# SMS_LITE_MAILBOX_4_MAILBOX_44242000h register map
Vendor: Texas Instruments
Peripheral module from a debugger description file (folder am62L).
Registers are 32-bit, read-write, reset 0x0 unless marked. A register's access mark holds for its fields unless they carry their own. Offsets are as the file gives them; lines under a group give offsets from that group; [hi:lo] are bit positions; {n}, {i} and the like mark numbered series; 'fields as' and 'values as' point back to an identical list; <NAME> marks a mode.

## mailbox
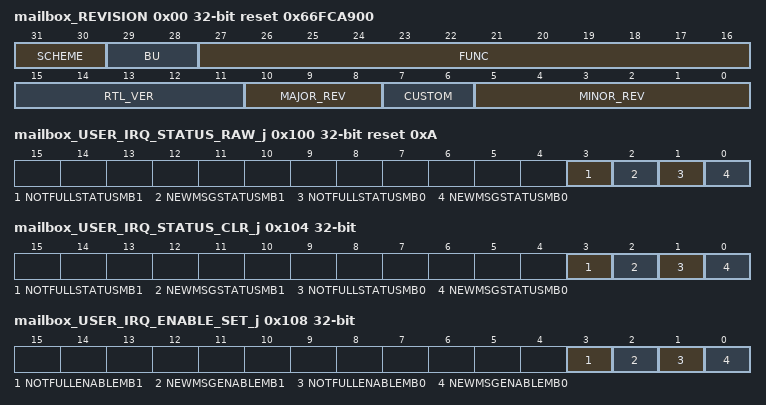
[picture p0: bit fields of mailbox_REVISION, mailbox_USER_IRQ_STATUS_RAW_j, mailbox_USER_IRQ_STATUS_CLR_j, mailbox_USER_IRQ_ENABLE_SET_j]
0x00 mailbox_REVISION ro reset 0x66FCA900 — This is the standard TI peripheral ID register that exists at address 0 in the peripheral space
  [31:30] SCHEME — Used to distinguish which ID numbering scheme is used. Reset Source: sms_custom_rst_mod_g_rst_n
  [29:28] BU — BU identifier Reset Source: sms_custom_rst_mod_g_rst_n
  [27:16] FUNC — Module family. Reset Source: sms_custom_rst_mod_g_rst_n
  [15:11] RTL_VER — RTL version. R of X.Y.R.Z Reset Source: sms_custom_rst_mod_g_rst_n
  [10:8] MAJOR_REV — Major revision. X of X.Y.R.Z Reset Source: sms_custom_rst_mod_g_rst_n
  [7:6] CUSTOM — Special version number Reset Source: sms_custom_rst_mod_g_rst_n
  [5:0] MINOR_REV — Minor revision. Y of X.Y.R.Z Reset Source: sms_custom_rst_mod_g_rst_n
0x10 mailbox_SYSCONFIG — This register contains parameters to control the whole Mailbox system. Provided for backwards compatibility with OMAP Mailbox. Only contains the soft reset.
  [0] SOFT_RESET — Module Software ResetThe bit is automatically reset by the hardware. During reads, it always returns 0.It has the same effect as the hardware reset.Writing a 0 has no effect. Writing a 1 will start a soft reset sequence and empty all the mailboxes Reset Source: sms_custom_rst_mod_g_rst_n
0x40 mailbox_MESSAGE_j — The message register stores the next to-be-read message of the mailbox. Read: Reads the next available message. Write: Add a message to this mailbox queue.
  [31:0] MESSAGE_VALUE — Message in Mailbox [a] Reset Source: sms_custom_rst_mod_g_rst_n
0x80 mailbox_FIFO_STATUS_j ro — The FIFO status register has the status of the Mailbox[a] FIFO
  [0] FIFO_FULL — Full flag for Mailbox m Reset Source: sms_custom_rst_mod_g_rst_n
0xC0 mailbox_MSG_STATUS_j ro — The message status register has the status of the messages in Mailbox[a]
  [2:0] NUM_MESSAGES — Number of messages in Mailbox[a] Reset Source: sms_custom_rst_mod_g_rst_n
0x100 mailbox_USER_IRQ_STATUS_RAW_j reset 0xA — The interrupt status register has the status for each event that may be responsible for the generation of an interrupt to the corresponding user .Software may also write 1 to a given bit to set this bit to test interrupt generation. It will activate the status bit for two cycles. This may still be masked, however. Write 0 has no effect.
  [3] NOTFULLSTATUSMB1 — 1 if Mailbox 1 is not full Reset Source: sms_custom_rst_mod_g_rst_n
  [2] NEWMSGSTATUSMB1 — 1 if there are messages present in Mailbox 1 Reset Source: sms_custom_rst_mod_g_rst_n
  [1] NOTFULLSTATUSMB0 — 1 if Mailbox 0 is not full Reset Source: sms_custom_rst_mod_g_rst_n
  [0] NEWMSGSTATUSMB0 — 1 if there are messages present in Mailbox 0 Reset Source: sms_custom_rst_mod_g_rst_n
0x104 mailbox_USER_IRQ_STATUS_CLR_j — The interrupt status register has the status for each event that may be responsible for the generation of an interrupt to the corresponding user combined with the corresponding MASK information.Software may also write 1 to a given bit to clear this bit. However, if the hardware still has pending, enabled events, the interrupt will fire again in two cycles.Write 0 has no effect.
  [3] NOTFULLSTATUSMB1 — 1 if Mailbox 1 is not full and this interrupt bit is enabled Reset Source: sms_custom_rst_mod_g_rst_n
  [2] NEWMSGSTATUSMB1 — 1 if there are messages present in Mailbox 1 and this interrupt bit is enabled Reset Source: sms_custom_rst_mod_g_rst_n
  [1] NOTFULLSTATUSMB0 — 1 if Mailbox 0 is not full and this interrupt bit is enabled Reset Source: sms_custom_rst_mod_g_rst_n
  [0] NEWMSGSTATUSMB0 — 1 if there are messages present in Mailbox 0 and this interrupt bit is enabled Reset Source: sms_custom_rst_mod_g_rst_n
0x108 mailbox_USER_IRQ_ENABLE_SET_j — The interrupt enable register allows software to mask/unmask the module internal source of interrupt for the user [a].Read value is the current enable bits for each interrupt source.Write 1 to a bit enables an interrupt source. Write 0 has no effect.
  [3] NOTFULLENABLEMB1 — Read value is current enable state for this interrupt. Write 1 enables the interrupt. Write 0 does nothing. Reset Source: sms_custom_rst_mod_g_rst_n
  [2] NEWMSGENABLEMB1 — Read value is current enable state for this interrupt. Write 1 enables the interrupt. Write 0 does nothing. Reset Source: sms_custom_rst_mod_g_rst_n
  [1] NOTFULLENABLEMB0 — Read value is current enable state for this interrupt. Write 1 enables the interrupt. Write 0 does nothing. Reset Source: sms_custom_rst_mod_g_rst_n
  [0] NEWMSGENABLEMB0 — Read value is current enable state for this interrupt. Write 1 enables the interrupt. Write 0 does nothing. Reset Source: sms_custom_rst_mod_g_rst_n
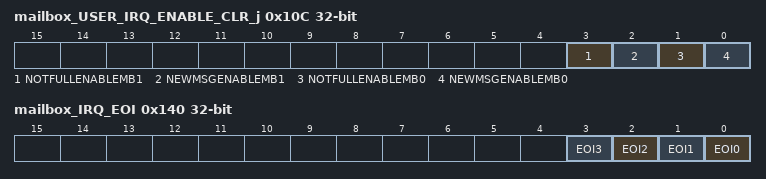
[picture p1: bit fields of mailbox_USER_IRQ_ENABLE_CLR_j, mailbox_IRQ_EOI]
0x10C mailbox_USER_IRQ_ENABLE_CLR_j — The interrupt enable register allows software to mask/unmask the module internal source of interrupt for the user [a].Read value is the current enable bits for each interrupt sourc.Write 1 to a bit disables an interrupt source. Write 0 has no effect.
  [3] NOTFULLENABLEMB1 — Read value is current enable state for this interrupt. Write 1 disables the interrupt. Write 0 does nothing. Reset Source: sms_custom_rst_mod_g_rst_n
  [2] NEWMSGENABLEMB1 — Read value is current enable state for this interrupt. Write 1 disables the interrupt. Write 0 does nothing. Reset Source: sms_custom_rst_mod_g_rst_n
  [1] NOTFULLENABLEMB0 — Read value is current enable state for this interrupt. Write 1 disables the interrupt. Write 0 does nothing. Reset Source: sms_custom_rst_mod_g_rst_n
  [0] NEWMSGENABLEMB0 — Read value is current enable state for this interrupt. Write 1 disables the interrupt. Write 0 does nothing. Reset Source: sms_custom_rst_mod_g_rst_n
0x140 mailbox_IRQ_EOI wo — This is the EOI register with which the software is enabled to do the interrupt clearance.
  [n] EOI{n} (n=0..3) — Software EOI signal for the user {n} interrupt Reset Source: sms_custom_rst_mod_g_rst_n
